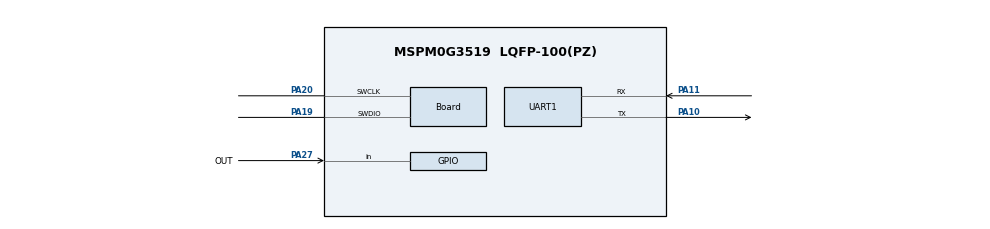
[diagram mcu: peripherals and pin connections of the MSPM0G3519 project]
//@cliArgs --device "MSPM0G351X" --package "LQFP-100(PZ)" --part "Default"
//@v2CliArgs --device "MSPM0G3519" --package "LQFP-100(PZ)"
// @cliArgs --board /ti/boards/LP_MSPM0G3519 --rtos nortos
// HC-SR501 PIR OUT on J3 pin 23 (PA27); text on UART0 PA10/PA11 (backchannel, J12/J13 on XDS)
const GPIO   = scripting.addModule("/ti/driverlib/GPIO", {}, false);
const GPIO1  = GPIO.addInstance();
const SYSCTL = scripting.addModule("/ti/driverlib/SYSCTL");
const UART   = scripting.addModule("/ti/driverlib/UART", {}, false);
const UART1  = UART.addInstance();

GPIO1.$name                              = "GPIO_PIR";
GPIO1.associatedPins.create(1);
GPIO1.associatedPins[0].$name            = "OUT";
GPIO1.associatedPins[0].direction        = "INPUT";
GPIO1.associatedPins[0].internalResistor = "PULL_DOWN";
GPIO1.associatedPins[0].pin.$assign      = "PA27";

const Board                       = scripting.addModule("/ti/driverlib/Board", {}, false);
Board.peripheral.$assign          = "DEBUGSS";
Board.peripheral.swclkPin.$assign = "PA20";
Board.peripheral.swdioPin.$assign = "PA19";

SYSCTL.forceDefaultClkConfig = true;
SYSCTL.clockTreeEn           = true;

UART1.$name                    = "UART_0";
UART1.targetBaudRate           = 115200;
UART1.uartClkDiv               = "8";
UART1.peripheral.$assign       = "UART0";
UART1.peripheral.rxPin.$assign = "PA11";
UART1.peripheral.txPin.$assign = "PA10";
